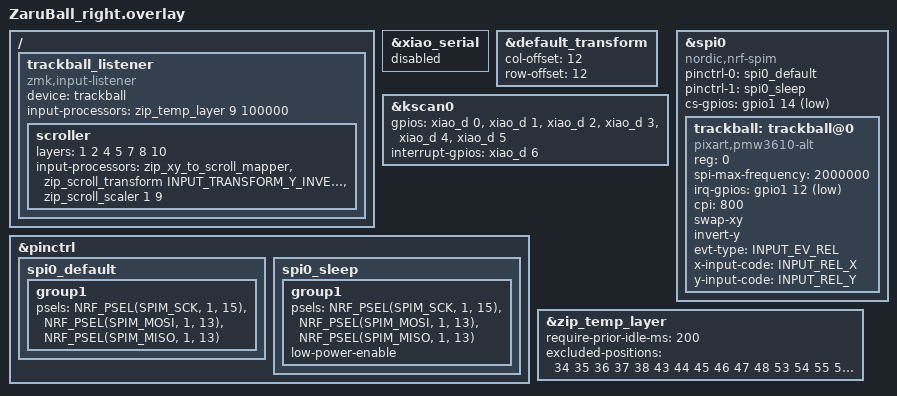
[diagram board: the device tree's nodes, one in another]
#include "ZaruBall.dtsi"
#include <dt-bindings/zmk/input_transform.h>
#include <input/processors.dtsi>
#include <zephyr/dt-bindings/input/input-event-codes.h>

&xiao_serial { status = "disabled"; };

// matrix transformでのピン数オフセット
&default_transform { // Offset of 7 because the left side has 2 columns
    col-offset = <12>;
    row-offset = <12>;
};

&kscan0 {
    gpios
        = <&xiao_d 0 GPIO_ACTIVE_HIGH>//M1
        , <&xiao_d 1 GPIO_ACTIVE_HIGH>//M2
        , <&xiao_d 2 GPIO_ACTIVE_HIGH>//M3
        , <&xiao_d 3 GPIO_ACTIVE_HIGH>//M4
        , <&xiao_d 4 GPIO_ACTIVE_HIGH>//M5
        , <&xiao_d 5 GPIO_ACTIVE_HIGH>//M6
        ;
    interrupt-gpios = <&xiao_d 6 (GPIO_ACTIVE_HIGH | GPIO_PULL_DOWN)>;//IGPIO
};

// pmw-3610-driverを動かすコード（古いブランチ:pointers-move-scroll）----------------------------------
&pinctrl {
    spi0_default: spi0_default {
        group1 {
            psels = <NRF_PSEL(SPIM_SCK, 1, 15)>, // SCLK
                <NRF_PSEL(SPIM_MOSI, 1, 13)>, // SDIO
                <NRF_PSEL(SPIM_MISO, 1, 13)>; // SDIO
        };
    };

    spi0_sleep: spi0_sleep {
        group1 {
            psels = <NRF_PSEL(SPIM_SCK, 1, 15)>,
                <NRF_PSEL(SPIM_MOSI, 1, 13)>,
                <NRF_PSEL(SPIM_MISO, 1, 13)>;
            low-power-enable;
        };
    };
};

&spi0 {
    status = "okay";
    compatible = "nordic,nrf-spim";
    pinctrl-0 = <&spi0_default>;
    pinctrl-1 = <&spi0_sleep>;
    pinctrl-names = "default", "sleep";
    cs-gpios = <&gpio1 14 GPIO_ACTIVE_LOW>; // CS

    trackball: trackball@0 {
        status = "okay";
        compatible = "pixart,pmw3610-alt";
        reg = <0>;
        spi-max-frequency = <2000000>;
        irq-gpios = <&gpio1 12 (GPIO_ACTIVE_LOW | GPIO_PULL_UP)>; // MOTION
        cpi = <800>;
        swap-xy;
        invert-y;
        evt-type = <INPUT_EV_REL>;
        x-input-code = <INPUT_REL_X>;
        y-input-code = <INPUT_REL_Y>;
    };
};

// You can find key number by entering config/info.json into https://zmk-physical-layout-converter.streamlit.app/
&zip_temp_layer {
    require-prior-idle-ms = <200>;
    excluded-positions = <
        34 // S
        35 // D
        36 // F
        37 // G
        38 // INS
        43 // [
        44 // H
        45 // J
        46 // K
        47 // L
        48 // ;
        53 // C
        54 // V
        55 // B
        56 // DELETE
        61 // ]
        62 // N
        63 // M
        64 // ,
    >;
};

/ {
  trackball_listener {
    compatible = "zmk,input-listener";
    device = <&trackball>;

    input-processors = <&zip_temp_layer 9 100000>;

    scroller {
        layers = <1 2 4 5 7 8 10>;
        input-processors = 
            <&zip_xy_to_scroll_mapper>,                         // Change scroll mode
            <&zip_scroll_transform INPUT_TRANSFORM_Y_INVERT>,   // Invert Y for scroll
            <&zip_scroll_scaler 1 9>;                           // 1/8 scroll scaler
    };
  };
};
